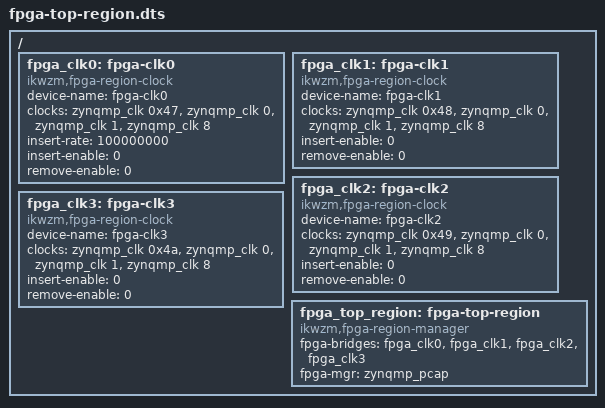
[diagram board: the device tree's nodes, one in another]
/dts-v1/; /plugin/;
/ {
	fragment@0 {
		target-path = "/";
		__overlay__ {
			fpga_clk0: fpga-clk0 {
				compatible    = "ikwzm,fpga-region-clock";
				device-name   = "fpga-clk0";
				clocks        = <&zynqmp_clk 0x47 &zynqmp_clk 0 &zynqmp_clk 1 &zynqmp_clk 8>;
				insert-rate   = <100000000>;
				insert-enable = <0>;
				remove-enable = <0>;
			};
			fpga_clk1: fpga-clk1 {
				compatible    = "ikwzm,fpga-region-clock";
				device-name   = "fpga-clk1";
				clocks        = <&zynqmp_clk 0x48 &zynqmp_clk 0 &zynqmp_clk 1 &zynqmp_clk 8>;
				insert-enable = <0>;
				remove-enable = <0>;
			};
			fpga_clk2: fpga-clk2 {
				compatible    = "ikwzm,fpga-region-clock";
				device-name   = "fpga-clk2";
				clocks        = <&zynqmp_clk 0x49 &zynqmp_clk 0 &zynqmp_clk 1 &zynqmp_clk 8>;
				insert-enable = <0>;
				remove-enable = <0>;
			};
			fpga_clk3: fpga-clk3 {
				compatible    = "ikwzm,fpga-region-clock";
				device-name   = "fpga-clk3";
				clocks        = <&zynqmp_clk 0x4a &zynqmp_clk 0 &zynqmp_clk 1 &zynqmp_clk 8>;
				insert-enable = <0>;
				remove-enable = <0>;
			};
			fpga_top_region: fpga-top-region {
				compatible    = "ikwzm,fpga-region-manager";
				fpga-bridges  = <&fpga_clk0 &fpga_clk1 &fpga_clk2 &fpga_clk3>;
				fpga-mgr      = <&zynqmp_pcap>;
			};
		};
        };
};
